# ESP32-H4 register map
Vendor: ESPRESSIF SYSTEMS (SHANGHAI) CO., LTD.; Series: ESP32 H-Series; File version: 1
CPU: RV32IMAC r0p0, little endian, no MPU, no FPU, 0 interrupt priority bits
Address unit: 32 bits
Registers are 32-bit, read-write, reset 0x0 unless marked. A register's access mark holds for its fields unless they carry their own. Offsets are from the block's base; [hi:lo] are bit positions; {n}, {i} and the like mark numbered series.

## INTERRUPT_CORE0 — Interrupt Controller (Core 0)
Base 0x6009A000
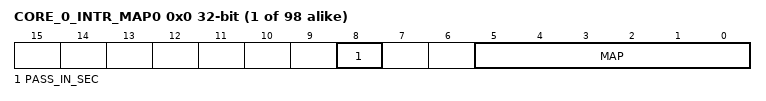
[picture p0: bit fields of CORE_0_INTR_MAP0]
{0x0+4i} CORE_0_INTR_MAP{i} (i=0..97)
  [8] PASS_IN_SEC, [5:0] MAP
{0x188+4i} CORE_0_INTR_STATUS{i} (i=0..2) ro — Status of interrupt sources within a 32-bit window
  [31:0] INT_STATUS_0 — Represents the status of the interrupt sources within interrupt-index-range 0 ~ 31. Each bit corresponds to one interrupt source 0:The corresponding interrupt source triggered an interrupt 1:No interrupt triggered
0x194 CORE_0_INTR_STATUS3 ro — Status register for interrupt sources 96 ~ 97
  [1:0] INT_STATUS_3 — Represents the status of the interrupt sources within interrupt-index-range 96 ~ 97. Each bit corresponds to one interrupt source 0:The corresponding interrupt source triggered an interrupt 1:No interrupt triggered
{0x198+4i} CORE_0_SRC_PASS_IN_SEC_STATUS{i} (i=0..2) ro — PASS_IN_SEC status for interrupt sources
  [31:0] INT_SRC_PASS_IN_SEC_STATUS_0 — Represents the PASS_IN_SEC status of the interrupt sources within interrupt-index-range 0 ~ 31. Each bit corresponds to one interrupt source 0:The corresponding interrupt source is not PASS_IN_SEC. 1:The corresponding interrupt source is PASS_IN_SEC.
0x1A4 CORE_0_SRC_PASS_IN_SEC_STATUS3 ro — PASS_IN_SEC status register for interrupt sources 96 ~ 97
  [1:0] INT_SRC_PASS_IN_SEC_STATUS_3 — Represents the PASS_IN_SEC status of the interrupt sources with interrupt-index-range 96 ~ 97. Each bit corresponds to one interrupt source 0:The corresponding interrupt source is not PASS_IN_SEC. 1:The corresponding interrupt source is PASS_IN_SEC.
0x1A8 SIG_IDX_ASSERT_IN_SEC — reserved
  [5:0] INT_SIG_IDX_ASSERT_IN_SEC
0x1AC SECURE_STATUS ro — reserved
  [31:0] INT_SECURE_STATUS
0x1B0 CLOCK_GATE — Interrupt clock gating configure register
  [0] REG_CLK_EN
0x7FC INTERRUPT_DATE — Version control register

## INTERRUPT_CORE1 — Interrupt Controller for Core 1
Base 0x6009B000
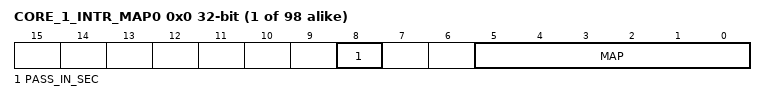
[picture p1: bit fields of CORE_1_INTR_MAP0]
{0x0+4i} CORE_1_INTR_MAP{i} (i=0..97) — Interrupt-matrix destination and PASS_IN_SEC routing for source {i}
  [8] PASS_IN_SEC, [5:0] MAP
{0x188+4i} CORE_1_INTR_STATUS{i} (i=0..2) ro — Status of interrupt sources within a 32-bit window
  [31:0] INT_STATUS
0x194 CORE_1_INTR_STATUS3 ro — Status register for interrupt sources 96 ~ 97
  [1:0] INT_STATUS_3
{0x198+4i} CORE_1_SRC_PASS_IN_SEC_STATUS{i} (i=0..2) ro — PASS_IN_SEC status for interrupt sources
  [31:0] INT_SRC_PASS_IN_SEC_STATUS
0x1A4 CORE_1_SRC_PASS_IN_SEC_STATUS3 ro — PASS_IN_SEC status register for interrupt sources 96 ~ 97
  [1:0] INT_SRC_PASS_IN_SEC_STATUS_3
0x1A8 SIG_IDX_ASSERT_IN_SEC — reserved
  [5:0] INT_SIG_IDX_ASSERT_IN_SEC
0x1AC SECURE_STATUS ro — reserved
  [31:0] INT_SECURE_STATUS
0x1B0 CLOCK_GATE — Interrupt clock gating configure register
  [0] REG_CLK_EN
0x7FC INTERRUPT_DATE — Version control register

## INTPRI — INTPRI Peripheral
Base 0x60005000
{0x90+4i} CPU_INTR_FROM_CPU{i} (i=0..3) — CPU_INTR_FROM_CPU_{i} mapping register
  [0] CPU_INTR — CPU_INTR_FROM_CPU_%s mapping register.
0xA0 DATE — Version control register
0xA4 CLOCK_GATE reset 0x1 — register description
  [0] CLK_EN — Need add description
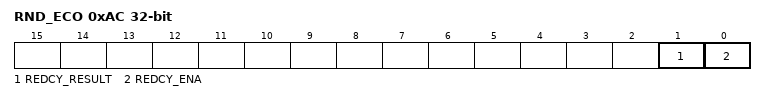
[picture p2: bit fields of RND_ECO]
0xAC RND_ECO access per field — redcy eco register.
  [1] REDCY_RESULT ro — Only reserved for ECO.
  [0] REDCY_ENA rw — Only reserved for ECO.
0xB0 RND_ECO_LOW — redcy eco low register.
  [31:0] REDCY_LOW — Only reserved for ECO.
0x3FC RND_ECO_HIGH reset 0xFFFFFFFF — redcy eco high register.
  [31:0] REDCY_HIGH — Only reserved for ECO.

## IO_MUX — Input/Output Multiplexer
Base 0x60092000
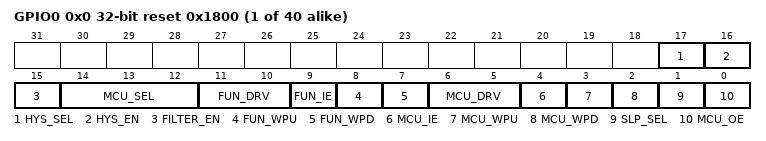
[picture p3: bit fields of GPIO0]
{0x0+4i} GPIO{i} (i=0..39) reset 0x1800 — IO MUX configuration register for GPIO{i}
  [17] HYS_SEL — Configures to choose the signal for enabling the hysteresis function for GPIO%s. \\ 0: Choose the output enable signal of eFuse\\ 1: Choose the output enable signal of IO_MUX_GPIO%s_HYS_EN\\
  [16] HYS_EN — Configures whether or not to enable the hysteresis function of the pin when IO_MUX_GPIO%s_HYS_SEL is set to 1.\\ 0: Disable\\ 1: Enable\\
  [15] FILTER_EN — Configures whether or not to enable filter for pin input signals.\\ 0: Disable\\ 1: Enable\\
  [14:12] MCU_SEL — Configures to select IO MUX function for this signal. \\ 0: Select Function 0\\ 1: Select Function 1\\ ......\\
  [11:10] FUN_DRV — Configures the drive strength of GPIO%s. \\ 0: ~5 mA\\ 1: ~10 mA\\ 2: ~20 mA\\ 3: ~40 mA\\
  [9] FUN_IE — Configures whether or not to enable input of GPIO%s.\\ 0: Disable\\ 1: Enable\\
  [8] FUN_WPU — Configures whether or not enable pull-up resistor of GPIO%s.\\ 0: Disable\\ 1: Enable\\
  [7] FUN_WPD — Configures whether or not to enable pull-down resistor of GPIO%s.\\ 0: Disable\\ 1: Enable\\
  [6:5] MCU_DRV — Configures the drive strength of GPIO%s during sleep mode. \\ 0: ~5 mA\\ 1: ~10 mA\\ 2: ~20 mA\\ 3: ~40 mA\\
  [4] MCU_IE — Configures whether or not to enable the input of GPIO%s during sleep mode.\\ 0: Disable\\ 1: Enable\\
  [3] MCU_WPU — Configures whether or not to enable pull-up resistor of GPIO%s during sleep mode. \\ 0: Disable\\ 1: Enable\\
  [2] MCU_WPD — Configure whether or not to enable pull-down resistor of GPIO%s in sleep mode.\\ 0: Disable\\ 1: Enable\\
  [1] SLP_SEL — Configures whether or not to enter sleep mode for GPIO%s.\\ 0: Not enter\\ 1: Enter\\
  [0] MCU_OE — Configures whether or not to enable the output of GPIO%s in sleep mode. 0: Disable\\ 1: Enable\\
0x1FC DATE — Version control register
